# H3 register map
Vendor: Allwinner; Series: H3; File version: 0.1
CPU: 0, little endian, MPU, no FPU, 0 interrupt priority bits
Registers are 32-bit, read-write, reset 0x0 unless marked. A register's access mark holds for its fields unless they carry their own. Offsets are from the block's base; [hi:lo] are bit positions; lines under a group give offsets from that group; {n}, {i} and the like mark numbered series; 'fields as' and 'values as' point back to an identical list.

## TCON0
Base 0x01C0C000
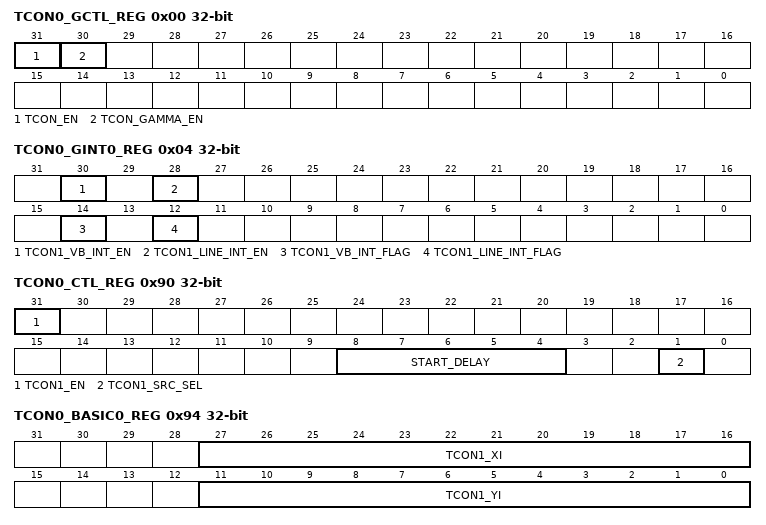
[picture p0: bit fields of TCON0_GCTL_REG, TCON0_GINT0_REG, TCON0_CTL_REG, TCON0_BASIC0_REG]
0x00 TCON0_GCTL_REG
  [31] TCON_EN — 0: disable 1: enable When it`s disabled, the module will be reset to idle state.
    0=disable; 1=enable When it`s disabled, the module will be reset to idle state
  [30] TCON_GAMMA_EN — 0: disable 1: enable
    0=disable; 1=enable
0x04 TCON0_GINT0_REG
  [30] TCON1_VB_INT_EN — 0: disable 1: enable
    0=disable; 1=enable
  [28] TCON1_LINE_INT_EN — 0: disable 1: enable
    0=disable; 1=enable
  [14] TCON1_VB_INT_FLAG — Asserted during vertical no-display period every frame. Write 0 to clear it.
  [12] TCON1_LINE_INT_FLAG — trigger when SY1 match the current TCON1 scan line Write 0 to clear it.
0x08 TCON0_GINT1_REG
  [11:0] TCON1_LINE_INT_NUM — scan line for TCON1 line trigger(including inactive lines) Setting it for the specified line for trigger1. Note: SY1 is writable only when LINE_TRG1 disable.
0x90 TCON0_CTL_REG
  [31] TCON1_EN — 0: disable 1: enable
    0=disable; 1=enable
  [8:4] START_DELAY — This is for DE1 and DE2
  [1] TCON1_SRC_SEL — 0: reserved 1: BLUE data(FIFO2 disable, RGB=0000FF)
    1=BLUE (BLUE data(FIFO2 disable, RGB=0000FF))
0x94 TCON0_BASIC0_REG
  [27:16] TCON1_XI — source width is X+1
  [11:0] TCON1_YI — source height is Y+1
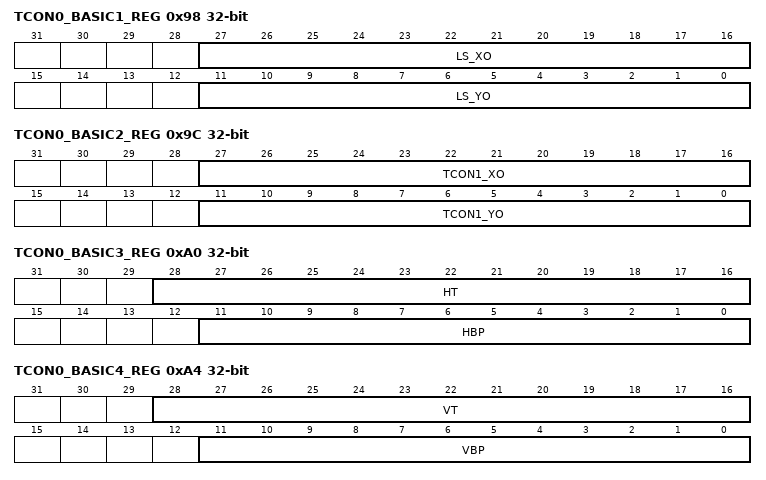
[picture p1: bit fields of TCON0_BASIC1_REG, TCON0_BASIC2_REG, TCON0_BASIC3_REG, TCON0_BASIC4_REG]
0x98 TCON0_BASIC1_REG
  [27:16] LS_XO — width is LS_XO+1
  [11:0] LS_YO — width is LS_YO+1 NOTE: This version LS_YO = TCON1_YI
0x9C TCON0_BASIC2_REG
  [27:16] TCON1_XO — width is TCON1_XO+1
  [11:0] TCON1_YO — height is TCON1_YO+1
0xA0 TCON0_BASIC3_REG
  [28:16] HT — horizontal total time Thcycle = (HT+1) * Thdclk
  [11:0] HBP — horizontal back porch Thbp = (HBP +1) * Thdclk
0xA4 TCON0_BASIC4_REG
  [28:16] VT — horizontal total time (in HD line) Tvt = VT/2 * Th
  [11:0] VBP — horizontal back porch (in HD line) Tvbp = (VBP +1) * Th
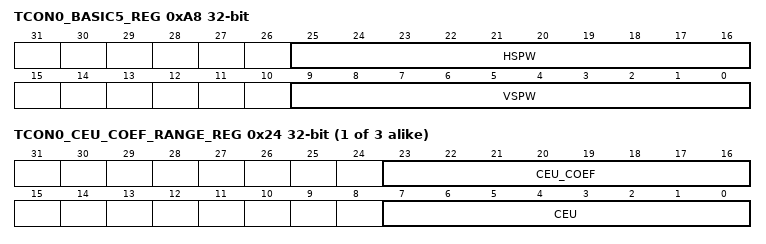
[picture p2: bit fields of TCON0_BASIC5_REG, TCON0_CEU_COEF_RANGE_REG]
0xA8 TCON0_BASIC5_REG
  [25:16] HSPW — horizontal Sync Pulse Width (in dclk) Thspw = (HSPW+1) * Tdclk Note: HT> (HSPW+1)
  [9:0] VSPW — vertical Sync Pulse Width (in lines) Tvspw = (VSPW+1) * Th Note: VT/2 > (VSPW+1)
0x100 TCON0_CEU_CTL_REG
  [31] CEU_EN — CEU_en 0: bypass 1: enable
    0=bypass; 1=enable
{0x11C+0x10*i} _N[{i}] (i=0..2) group
  0x00 TCON0_CEU_COEF_ADD_REG
    [18:0] CEU_COEF_ADD_VALUE — signed 19bit value, range of (-16384, 16384) N=0: Rc N=1: Gc N=2: Bc
  0x24 TCON0_CEU_COEF_RANGE_REG
    [23:16] CEU_COEF — _Range_Min unsigned 8bit value, range of [0,255]
    [7:0] CEU — Coef _Range_Max unsigned 8bit value, range of [0,255]
  0x1E8 TCON0_FILL_BEGIN_REG
    [23:0] FILL_BEGIN
  0x1EC TCON0_FILL_END_REG
    [23:0] FILL_END
  0x1F0 TCON0_FILL_DATA_REG
    [23:0] FILL_VALUE
0x300 TCON0_FILL_CTL_REG
  [31] TCON1_FILL_EN — 0: bypass 1: enable
    0=bypass; 1=enable

## TCON1
Base 0x01C0D000
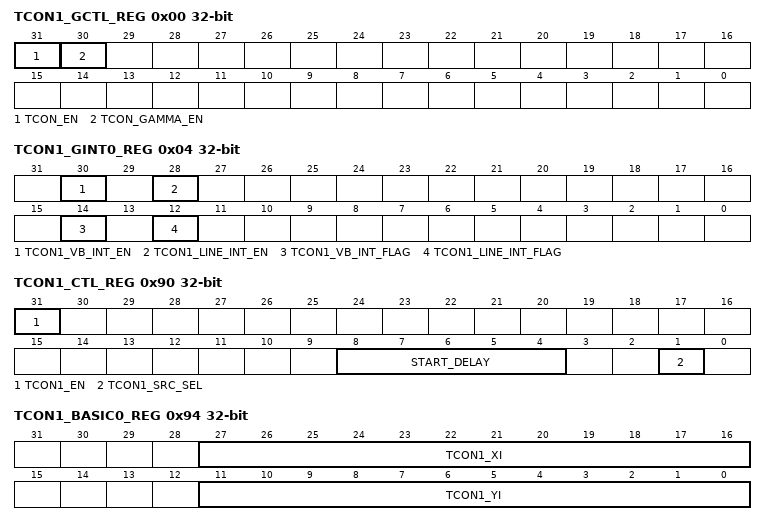
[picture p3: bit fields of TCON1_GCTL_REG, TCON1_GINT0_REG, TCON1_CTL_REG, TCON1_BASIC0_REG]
0x00 TCON1_GCTL_REG
  [31] TCON_EN — 0: disable 1: enable When it`s disabled, the module will be reset to idle state.
    0=disable; 1=enable When it`s disabled, the module will be reset to idle state
  [30] TCON_GAMMA_EN — 0: disable 1: enable
    0=disable; 1=enable
0x04 TCON1_GINT0_REG
  [30] TCON1_VB_INT_EN — 0: disable 1: enable
    0=disable; 1=enable
  [28] TCON1_LINE_INT_EN — 0: disable 1: enable
    0=disable; 1=enable
  [14] TCON1_VB_INT_FLAG — Asserted during vertical no-display period every frame. Write 0 to clear it.
  [12] TCON1_LINE_INT_FLAG — trigger when SY1 match the current TCON1 scan line Write 0 to clear it.
0x08 TCON1_GINT1_REG
  [11:0] TCON1_LINE_INT_NUM — scan line for TCON1 line trigger(including inactive lines) Setting it for the specified line for trigger 1. Note: SY1 is writable only when LINE_TRG1 disable.
0x90 TCON1_CTL_REG — TCON1 control register
  [31] TCON1_EN — 0: disable 1: enable
    0=disable; 1=enable
  [8:4] START_DELAY — This is for DE1 and DE2
  [1] TCON1_SRC_SEL — 00: DE 0 01: BLUE data(FIFO2 disable,RGB = 0000FF)
0x94 TCON1_BASIC0_REG — TCON1 basic timing register0
  [27:16] TCON1_XI — source width is X+1
  [11:0] TCON1_YI — source height is Y+1
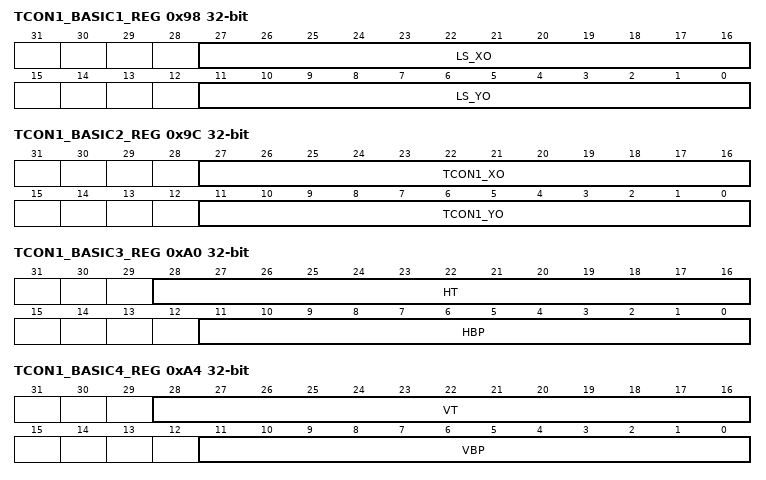
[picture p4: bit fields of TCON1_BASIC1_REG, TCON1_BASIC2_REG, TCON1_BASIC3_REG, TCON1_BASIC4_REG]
0x98 TCON1_BASIC1_REG — TCON1 basic timing register1
  [27:16] LS_XO — width is LS_XO+1
  [11:0] LS_YO — width is LS_YO+1 NOTE: this version LS_YO = TCON1_YI
0x9C TCON1_BASIC2_REG — TCON1 basic timing register2
  [27:16] TCON1_XO — width is TCON1_XO+1
  [11:0] TCON1_YO — height is TCON1_YO+1
0xA0 TCON1_BASIC3_REG — TCON1 basic timing register3
  [28:16] HT — horizontal total time Thcycle = (HT+1) * Thdclk
  [11:0] HBP — horizontal back porch Thbp = (HBP +1) * Thdclk
0xA4 TCON1_BASIC4_REG — TCON1 basic timing register4
  [28:16] VT — horizontal total time (in HD line) Tvt = VT/2 * Th
  [11:0] VBP — horizontal back porch (in HD line) Tvbp = (VBP +1) * Th
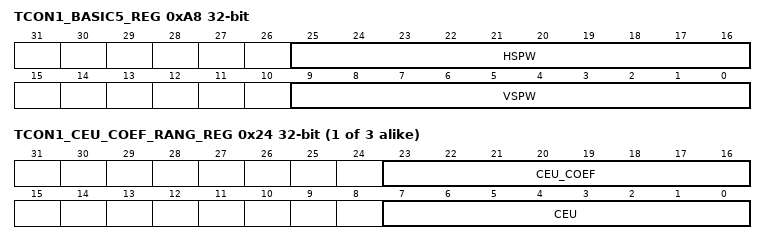
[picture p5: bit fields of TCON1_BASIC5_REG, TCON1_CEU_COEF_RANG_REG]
0xA8 TCON1_BASIC5_REG — TCON1 basic timing register5
  [25:16] HSPW — horizontal Sync Pulse Width (in dclk) Thspw = (HSPW+1) * Tdclk Note: HT> (HSPW+1)
  [9:0] VSPW — vertical Sync Pulse Width (in lines) Tvspw = (VSPW+1) * Th Note: VT/2 > (VSPW+1)
0x100 TCON1_CEU_CTL_REG
  [31] CEU_EN — CEU_en 0: bypass 1: enable
    0=bypass; 1=enable
0x110 TCON1_CEU_COEF_MUL_REG_0
  [12:0] CEU_COEF_MUL_VALUE — signed 13bit value, range of (-16,16) N=0: Rr N=1: Rg N=2: Rb N=4: Gr N=5: Gg N=6: Gb N=8: Br N=9: Bg N=10: Bb
0x114 TCON1_CEU_COEF_MUL_REG_1 — TCON1_CEU_COEF_MUL_REG_0
  fields as TCON1_CEU_COEF_MUL_REG_0
0x118 TCON1_CEU_COEF_MUL_REG_2 — TCON1_CEU_COEF_MUL_REG_0
  fields as TCON1_CEU_COEF_MUL_REG_0
{0x11C+0x10*i} _N[{i}] (i=0..2) group
  0x00 TCON1_CEU_COEF_ADD_REG
    [18:0] CEU_COEF_ADD_VALUE — signed 19bit value, range of (-16384, 16384) N=0: Rc N=1: Gc N=2: Bc
  0x24 TCON1_CEU_COEF_RANG_REG
    [23:16] CEU_COEF — _Range_Min unsigned 8bit value, range of [0,255]
    [7:0] CEU — Coef _Range_Max unsigned 8bit value, range of [0,255]
  0x1E8 TCON1_FILL_BEGIN_REG — TCON1 fill data begin register (N=0,1,2)
    [23:0] FILL_BEGIN
  0x1EC TCON1_FILL_END_REG — TCON1 fill data end register (N=0,1,2)
    [23:0] FILL_END
  0x1F0 TCON1_FILL_DATA_REG
    [23:0] FILL_VALUE
{0x110+4i} TCON1_CEU_COEF_MUL_REG_{i} (i=4..6) — TCON1_CEU_COEF_MUL_REG_0
  fields as TCON1_CEU_COEF_MUL_REG_0
{0x110+4i} TCON1_CEU_COEF_MUL_REG_{i} (i=8..10) — TCON1_CEU_COEF_MUL_REG_0
  fields as TCON1_CEU_COEF_MUL_REG_0
0x300 TCON1_FILL_CTL_REG — TCON1 fill data control register
  [31] TCON1_FILL_EN — 0: bypass 1: enable
    0=bypass; 1=enable
